# STM32F410RBT7 register map
File version: 1.0
Registers are 32-bit, access not given, reset 0x0 unless marked. A register's access mark holds for its fields unless they carry their own. Offsets are from the block's base; [hi:lo] are bit positions; {n}, {i} and the like mark numbered series.

## DAC1
Base 0x40007400
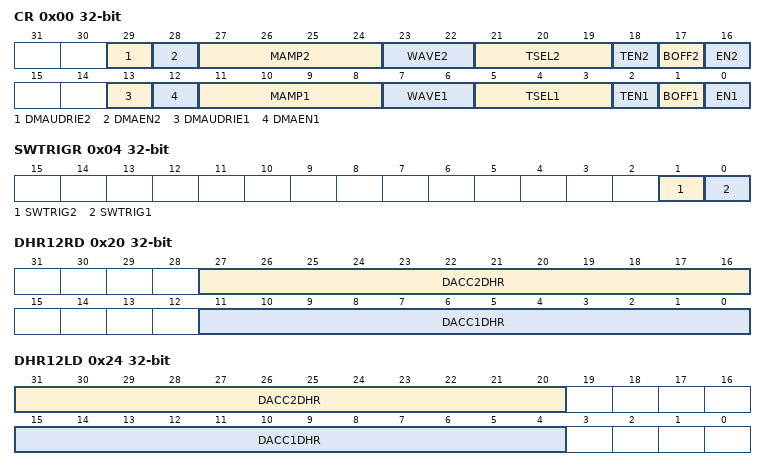
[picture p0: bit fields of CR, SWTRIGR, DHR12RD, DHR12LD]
0x00 CR
  [29] DMAUDRIE2, [28] DMAEN2, [27:24] MAMP2, [23:22] WAVE2, [21:19] TSEL2, [18] TEN2, [17] BOFF2, [16] EN2, [13] DMAUDRIE1, [12] DMAEN1, [11:8] MAMP1, [7:6] WAVE1, [5:3] TSEL1, [2] TEN1, [1] BOFF1, [0] EN1
0x04 SWTRIGR
  [1] SWTRIG2, [0] SWTRIG1
0x08 DHR12R1
  [11:0] DACC1DHR
0x0C DHR12L1
  [15:4] DACC1DHR
0x10 DHR8R1
  [7:0] DACC1DHR
0x14 DHR12R2
  [11:0] DACC2DHR
0x18 DHR12L2
  [15:4] DACC2DHR
0x1C DHR8R2
  [7:0] DACC2DHR
0x20 DHR12RD
  [27:16] DACC2DHR, [11:0] DACC1DHR
0x24 DHR12LD
  [31:20] DACC2DHR, [15:4] DACC1DHR
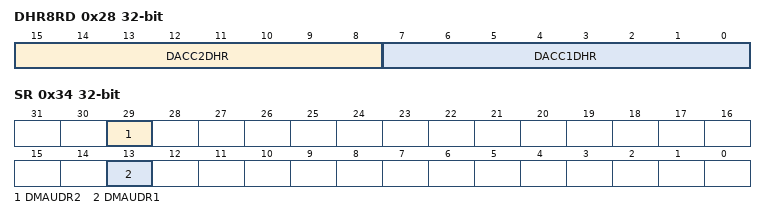
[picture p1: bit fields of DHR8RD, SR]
0x28 DHR8RD
  [15:8] DACC2DHR, [7:0] DACC1DHR
0x2C DOR1
  [11:0] DACC1DOR
0x30 DOR2
  [11:0] DACC2DOR
0x34 SR
  [29] DMAUDR2, [13] DMAUDR1

## ADC1
Base 0x40012000
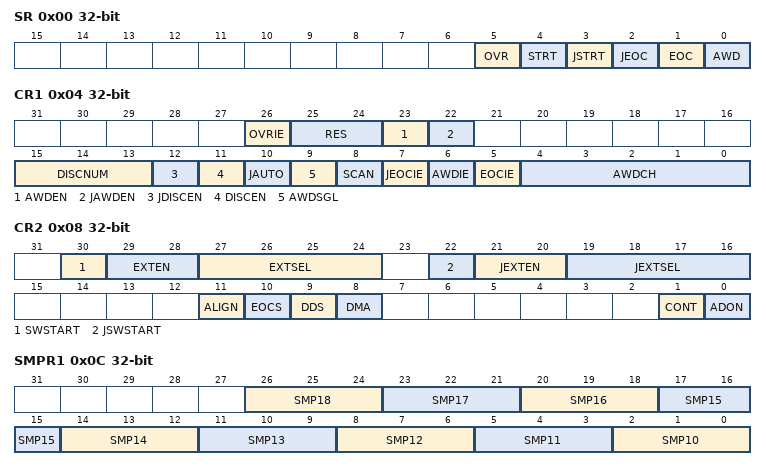
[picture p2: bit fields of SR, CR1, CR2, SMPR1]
0x00 SR
  [5] OVR, [4] STRT, [3] JSTRT, [2] JEOC, [1] EOC, [0] AWD
0x04 CR1
  [26] OVRIE, [25:24] RES, [23] AWDEN, [22] JAWDEN, [15:13] DISCNUM, [12] JDISCEN, [11] DISCEN, [10] JAUTO, [9] AWDSGL, [8] SCAN, [7] JEOCIE, [6] AWDIE, [5] EOCIE, [4:0] AWDCH
0x08 CR2
  [30] SWSTART, [29:28] EXTEN, [27:24] EXTSEL, [22] JSWSTART, [21:20] JEXTEN, [19:16] JEXTSEL, [11] ALIGN, [10] EOCS, [9] DDS, [8] DMA, [1] CONT, [0] ADON
0x0C SMPR1
  [3n-28:3n-30] SMP{n} (n=10..18)
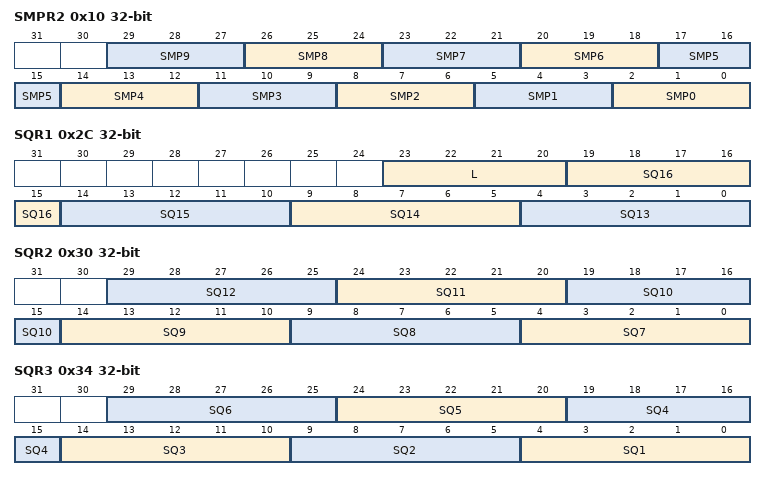
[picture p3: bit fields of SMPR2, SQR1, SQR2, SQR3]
0x10 SMPR2
  [3n+2:3n] SMP{n} (n=0..9)
{0x10+4i} JOFR{i} (i=1..4)
  [11:0] JOFFSET{i}
0x24 HTR
  [11:0] HT
0x28 LTR
  [11:0] LT
0x2C SQR1
  [23:20] L, [5n-61:5n-65] SQ{n} (n=13..16)
0x30 SQR2
  [5n-31:5n-35] SQ{n} (n=7..12)
0x34 SQR3
  [5n-1:5n-5] SQ{n} (n=1..6)
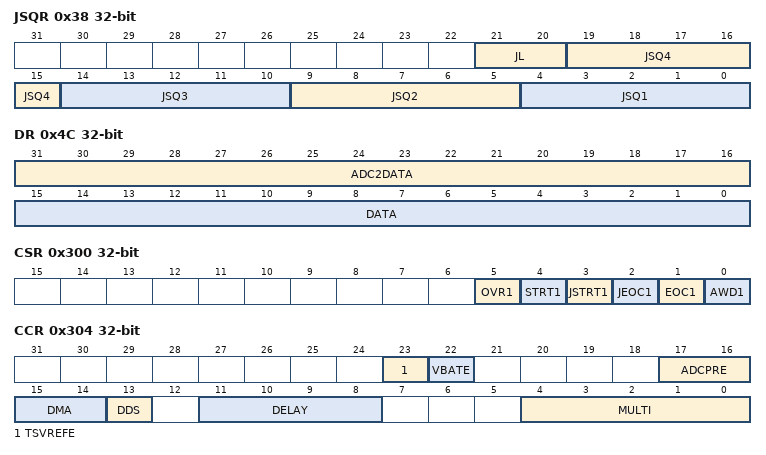
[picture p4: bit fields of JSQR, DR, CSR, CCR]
0x38 JSQR
  [21:20] JL, [5n-1:5n-5] JSQ{n} (n=1..4)
{0x38+4i} JDR{i} (i=1..4)
  [15:0] JDATA
0x4C DR
  [31:16] ADC2DATA, [15:0] DATA
0x300 CSR
  [5] OVR1, [4] STRT1, [3] JSTRT1, [2] JEOC1, [1] EOC1, [0] AWD1
0x304 CCR
  [23] TSVREFE, [22] VBATE, [17:16] ADCPRE, [15:14] DMA, [13] DDS, [11:8] DELAY, [4:0] MULTI
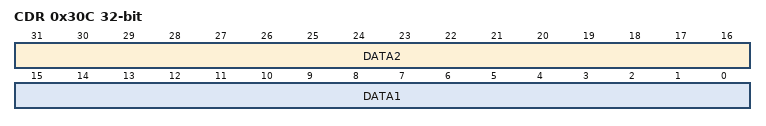
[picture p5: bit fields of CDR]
0x30C CDR
  [31:16] DATA2, [15:0] DATA1

## SYSCFG
Base 0x40013800
0x00 MEMRMP
  [1:0] MEM_MODE
0x04 PMC
  [16] ADC1DC2
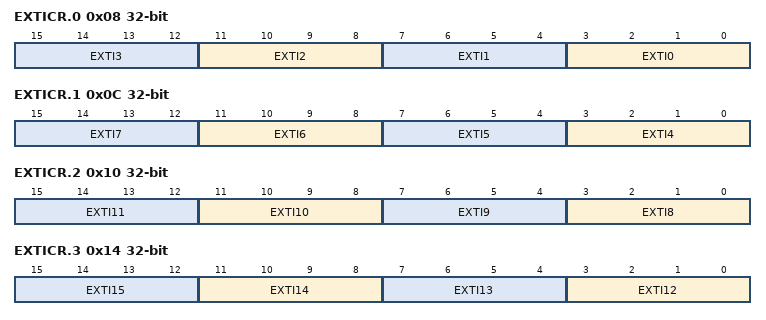
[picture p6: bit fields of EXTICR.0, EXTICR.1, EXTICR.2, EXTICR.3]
0x08 EXTICR.0
  [4n+3:4n] EXTI{n} (n=0..3)
0x0C EXTICR.1
  [4n-13:4n-16] EXTI{n} (n=4..7)
0x10 EXTICR.2
  [4n-29:4n-32] EXTI{n} (n=8..11)
0x14 EXTICR.3
  [4n-45:4n-48] EXTI{n} (n=12..15)
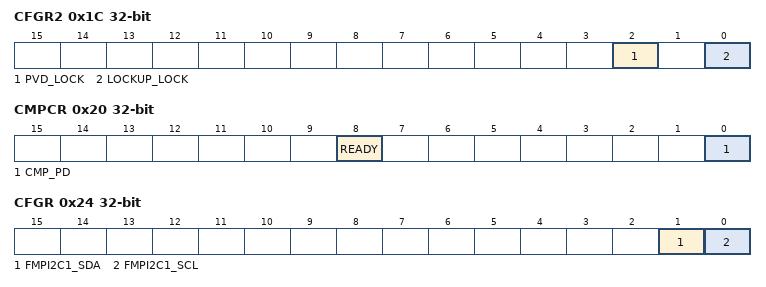
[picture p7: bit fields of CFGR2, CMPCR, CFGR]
0x1C CFGR2
  [2] PVD_LOCK, [0] LOCKUP_LOCK
0x20 CMPCR
  [8] READY, [0] CMP_PD
0x24 CFGR
  [1] FMPI2C1_SDA, [0] FMPI2C1_SCL

## EXTI
Base 0x40013C00
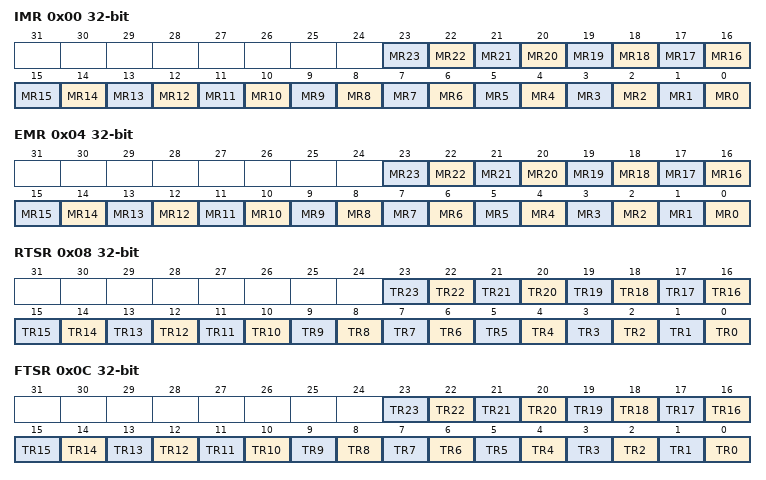
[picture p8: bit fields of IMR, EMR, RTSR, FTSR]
0x00 IMR
  [n] MR{n} (n=0..23)
0x04 EMR
  [n] MR{n} (n=0..23)
0x08 RTSR
  [n] TR{n} (n=0..23)
0x0C FTSR
  [n] TR{n} (n=0..23)
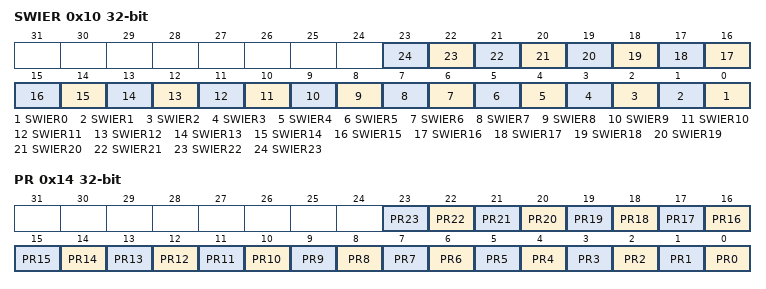
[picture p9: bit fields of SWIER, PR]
0x10 SWIER
  [n] SWIER{n} (n=0..23)
0x14 PR
  [n] PR{n} (n=0..23)

## GPIOA
Base 0x40020000
Same registers: GPIOB 0x40020400, GPIOC 0x40020800, GPIOH 0x40021C00
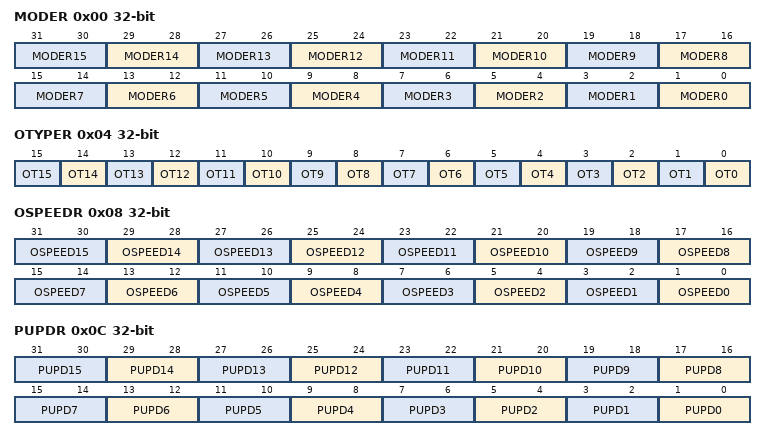
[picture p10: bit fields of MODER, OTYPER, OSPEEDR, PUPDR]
0x00 MODER
  [2n+1:2n] MODER{n} (n=0..15)
0x04 OTYPER
  [n] OT{n} (n=0..15)
0x08 OSPEEDR
  [2n+1:2n] OSPEED{n} (n=0..15)
0x0C PUPDR
  [2n+1:2n] PUPD{n} (n=0..15)
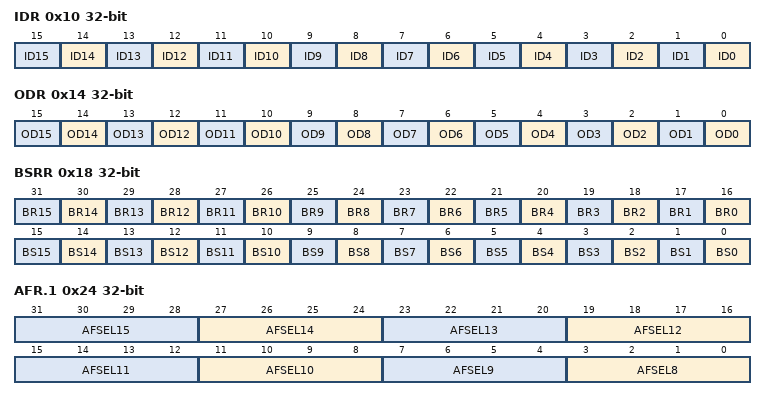
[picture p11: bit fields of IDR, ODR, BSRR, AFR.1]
0x10 IDR
  [n] ID{n} (n=0..15)
0x14 ODR
  [n] OD{n} (n=0..15)
0x18 BSRR
  [n+16] BR{n} (n=0..15), [n] BS{n} (n=0..15)
0x1C LCKR
0x20 AFR.0
0x24 AFR.1
  [4n-29:4n-32] AFSEL{n} (n=8..15)

## CRC
Base 0x40023000
0x00 DR
0x04 IDR 8-bit
0x08 CR
  [0] RESET

## RCC
Base 0x40023800
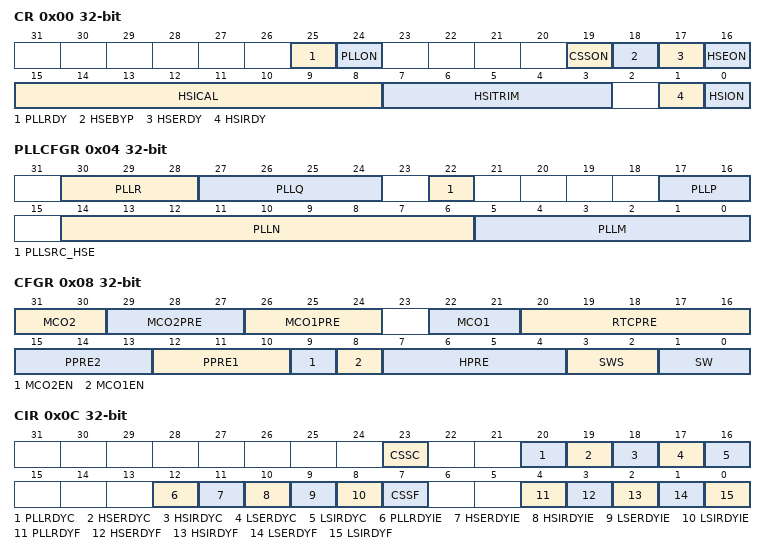
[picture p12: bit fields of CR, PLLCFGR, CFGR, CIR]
0x00 CR
  [25] PLLRDY, [24] PLLON, [19] CSSON, [18] HSEBYP, [17] HSERDY, [16] HSEON, [15:8] HSICAL, [7:3] HSITRIM, [1] HSIRDY, [0] HSION
0x04 PLLCFGR
  [30:28] PLLR, [27:24] PLLQ, [22] PLLSRC_HSE, [17:16] PLLP, [14:6] PLLN, [5:0] PLLM
0x08 CFGR
  [31:30] MCO2, [29:27] MCO2PRE, [26:24] MCO1PRE, [22:21] MCO1, [20:16] RTCPRE, [15:13] PPRE2, [12:10] PPRE1, [9] MCO2EN, [8] MCO1EN, [7:4] HPRE, [3:2] SWS, [1:0] SW
0x0C CIR
  [23] CSSC, [20] PLLRDYC, [19] HSERDYC, [18] HSIRDYC, [17] LSERDYC, [16] LSIRDYC, [12] PLLRDYIE, [11] HSERDYIE, [10] HSIRDYIE, [9] LSERDYIE, [8] LSIRDYIE, [7] CSSF, [4] PLLRDYF, [3] HSERDYF, [2] HSIRDYF, [1] LSERDYF, [0] LSIRDYF
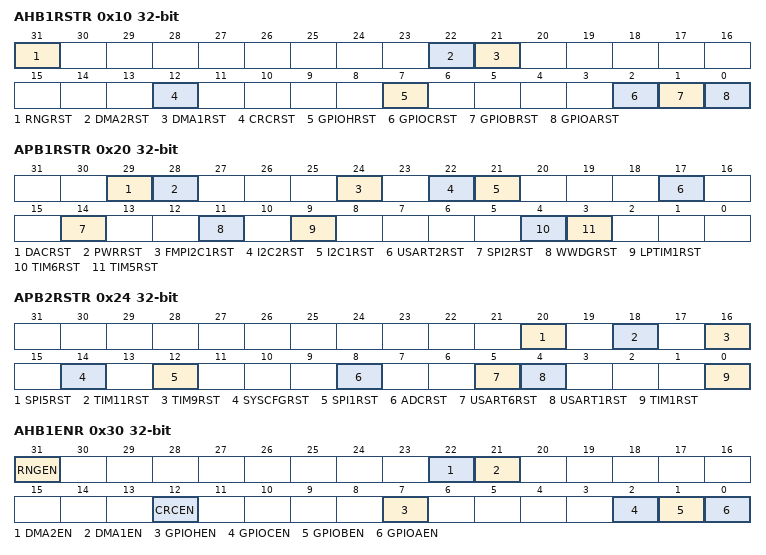
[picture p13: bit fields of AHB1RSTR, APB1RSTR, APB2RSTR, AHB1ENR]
0x10 AHB1RSTR
  [31] RNGRST, [22] DMA2RST, [21] DMA1RST, [12] CRCRST, [7] GPIOHRST, [2] GPIOCRST, [1] GPIOBRST, [0] GPIOARST
0x20 APB1RSTR
  [29] DACRST, [28] PWRRST, [24] FMPI2C1RST, [22] I2C2RST, [21] I2C1RST, [17] USART2RST, [14] SPI2RST, [11] WWDGRST, [9] LPTIM1RST, [4] TIM6RST, [3] TIM5RST
0x24 APB2RSTR
  [20] SPI5RST, [18] TIM11RST, [16] TIM9RST, [14] SYSCFGRST, [12] SPI1RST, [8] ADCRST, [5] USART6RST, [4] USART1RST, [0] TIM1RST
0x30 AHB1ENR
  [31] RNGEN, [22] DMA2EN, [21] DMA1EN, [12] CRCEN, [7] GPIOHEN, [2] GPIOCEN, [1] GPIOBEN, [0] GPIOAEN
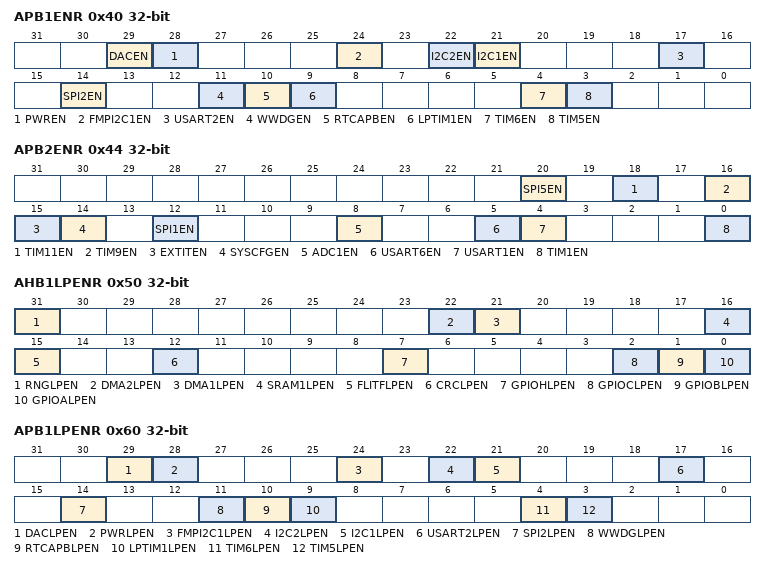
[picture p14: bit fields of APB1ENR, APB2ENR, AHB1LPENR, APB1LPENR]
0x40 APB1ENR
  [29] DACEN, [28] PWREN, [24] FMPI2C1EN, [22] I2C2EN, [21] I2C1EN, [17] USART2EN, [14] SPI2EN, [11] WWDGEN, [10] RTCAPBEN, [9] LPTIM1EN, [4] TIM6EN, [3] TIM5EN
0x44 APB2ENR
  [20] SPI5EN, [18] TIM11EN, [16] TIM9EN, [15] EXTITEN, [14] SYSCFGEN, [12] SPI1EN, [8] ADC1EN, [5] USART6EN, [4] USART1EN, [0] TIM1EN
0x50 AHB1LPENR
  [31] RNGLPEN, [22] DMA2LPEN, [21] DMA1LPEN, [16] SRAM1LPEN, [15] FLITFLPEN, [12] CRCLPEN, [7] GPIOHLPEN, [2] GPIOCLPEN, [1] GPIOBLPEN, [0] GPIOALPEN
0x60 APB1LPENR
  [29] DACLPEN, [28] PWRLPEN, [24] FMPI2C1LPEN, [22] I2C2LPEN, [21] I2C1LPEN, [17] USART2LPEN, [14] SPI2LPEN, [11] WWDGLPEN, [10] RTCAPBLPEN, [9] LPTIM1LPEN, [4] TIM6LPEN, [3] TIM5LPEN
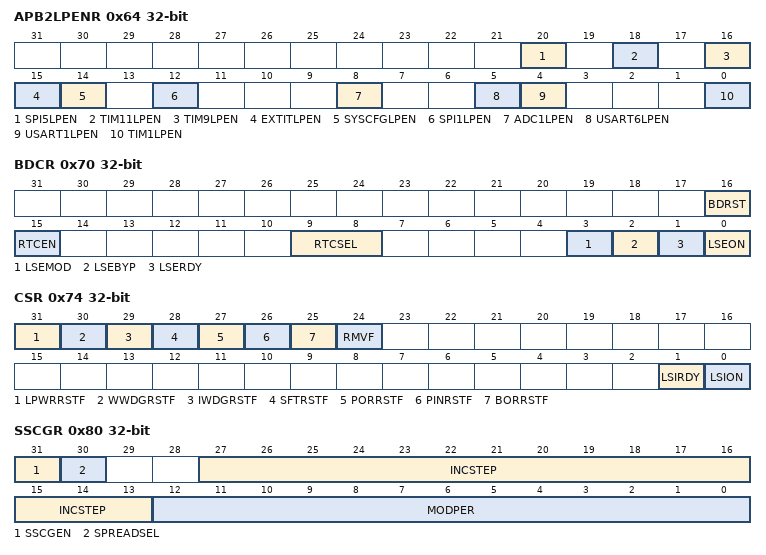
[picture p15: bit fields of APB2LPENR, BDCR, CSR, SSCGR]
0x64 APB2LPENR
  [20] SPI5LPEN, [18] TIM11LPEN, [16] TIM9LPEN, [15] EXTITLPEN, [14] SYSCFGLPEN, [12] SPI1LPEN, [8] ADC1LPEN, [5] USART6LPEN, [4] USART1LPEN, [0] TIM1LPEN
0x70 BDCR
  [16] BDRST, [15] RTCEN, [9:8] RTCSEL, [3] LSEMOD, [2] LSEBYP, [1] LSERDY, [0] LSEON
0x74 CSR
  [31] LPWRRSTF, [30] WWDGRSTF, [29] IWDGRSTF, [28] SFTRSTF, [27] PORRSTF, [26] PINRSTF, [25] BORRSTF, [24] RMVF, [1] LSIRDY, [0] LSION
0x80 SSCGR
  [31] SSCGEN, [30] SPREADSEL, [27:13] INCSTEP, [12:0] MODPER
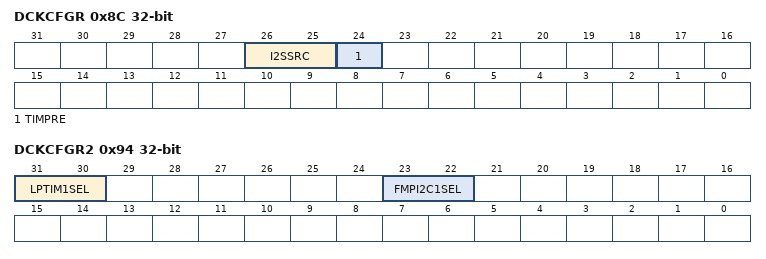
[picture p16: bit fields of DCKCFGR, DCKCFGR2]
0x8C DCKCFGR
  [26:25] I2SSRC, [24] TIMPRE
0x90 CKGATENR
0x94 DCKCFGR2
  [31:30] LPTIM1SEL, [23:22] FMPI2C1SEL

## FLASH
Base 0x40023C00
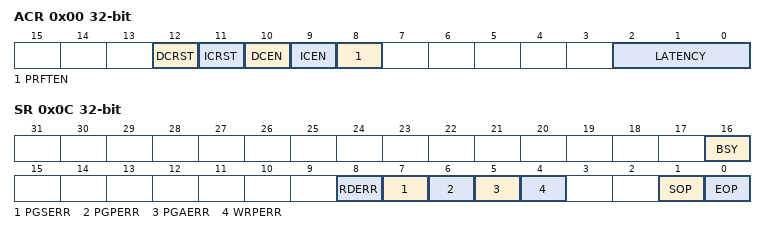
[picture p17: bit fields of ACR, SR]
0x00 ACR
  [12] DCRST, [11] ICRST, [10] DCEN, [9] ICEN, [8] PRFTEN, [2:0] LATENCY
0x04 KEYR
0x08 OPTKEYR
0x0C SR
  [16] BSY, [8] RDERR, [7] PGSERR, [6] PGPERR, [5] PGAERR, [4] WRPERR, [1] SOP, [0] EOP
0x10 CR
  [31] LOCK, [25] ERRIE, [24] EOPIE, [16] STRT, [9:8] PSIZE, [7:3] SNB, [2] MER, [1] SER, [0] PG
0x14 OPTCR
  [27:16] nWRP, [15:8] RDP, [7] nRST_STDBY, [6] nRST_STOP, [5] WDG_SW, [3:2] BOR_LEV, [1] OPTSTRT, [0] OPTLOCK
0x18 OPTCR1
  [27:16] nWRP

## DMA1
Base 0x40026000
Same registers: DMA2 0x40026400
0x00 LISR
  [27] TCIF3, [26] HTIF3, [25] TEIF3, [24] DMEIF3, [22] FEIF3, [21] TCIF2, [20] HTIF2, [19] TEIF2, [18] DMEIF2, [16] FEIF2, [11] TCIF1, [10] HTIF1, [9] TEIF1, [8] DMEIF1, [6] FEIF1, [5] TCIF0, [4] HTIF0, [3] TEIF0, [2] DMEIF0, [0] FEIF0
0x04 HISR
  [27] TCIF7, [26] HTIF7, [25] TEIF7, [24] DMEIF7, [22] FEIF7, [21] TCIF6, [20] HTIF6, [19] TEIF6, [18] DMEIF6, [16] FEIF6, [11] TCIF5, [10] HTIF5, [9] TEIF5, [8] DMEIF5, [6] FEIF5, [5] TCIF4, [4] HTIF4, [3] TEIF4, [2] DMEIF4, [0] FEIF4
0x08 LIFCR
  [27] CTCIF3, [26] CHTIF3, [25] CTEIF3, [24] CDMEIF3, [22] CFEIF3, [21] CTCIF2, [20] CHTIF2, [19] CTEIF2, [18] CDMEIF2, [16] CFEIF2, [11] CTCIF1, [10] CHTIF1, [9] CTEIF1, [8] CDMEIF1, [6] CFEIF1, [5] CTCIF0, [4] CHTIF0, [3] CTEIF0, [2] CDMEIF0, [0] CFEIF0
0x0C HIFCR
  [27] CTCIF7, [26] CHTIF7, [25] CTEIF7, [24] CDMEIF7, [22] CFEIF7, [21] CTCIF6, [20] CHTIF6, [19] CTEIF6, [18] CDMEIF6, [16] CFEIF6, [11] CTCIF5, [10] CHTIF5, [9] CTEIF5, [8] CDMEIF5, [6] CFEIF5, [5] CTCIF4, [4] CHTIF4, [3] CTEIF4, [2] CDMEIF4, [0] CFEIF4
{0x10+0x18*i} CR{i} (i=0..7)
{0x14+0x18*i} NDTR{i} (i=0..7)
{0x18+0x18*i} PAR{i} (i=0..7)
{0x1C+0x18*i} M0AR{i} (i=0..7)
{0x20+0x18*i} M1AR{i} (i=0..7)
{0x24+0x18*i} FCR{i} (i=0..7)

## RNG
Base 0x40080000
0x00 CR
  [3] IE, [2] RNGEN
0x04 SR
  [6] SEIS, [5] CEIS, [2] SECS, [1] CECS, [0] DRDY
0x08 DR

## DBGMCU
Base 0xE0042000
0x00 IDCODE
  [31:16] REV_ID, [11:0] DEV_ID
0x04 CR
  [7:6] TRACE_MODE, [5] TRACE_IOEN, [2] DBG_STANDBY, [1] DBG_STOP, [0] DBG_SLEEP
0x08 APB1FZ
  [26] DBG_CAN2_STOP, [25] DBG_CAN1_STOP, [24] DBG_I2C4_SMBUS_TIMEOUT, [22] DBG_I2C2_SMBUS_TIMEOUT, [21] DBG_I2C1_SMBUS_TIMEOUT, [12] DBG_IWDG_STOP, [11] DBG_WWDG_STOP, [10] DBG_RTC_STOP, [4] DBG_TIM6_STOP, [3] DBG_TIM5_STOP
0x0C APB2FZ
  [18] DBG_TIM11_STOP, [16] DBG_TIM9_STOP, [0] DBG_TIM1_STOP
